# M3351 register map
File version: 1.0
Registers are 32-bit, read-write, reset 0x0 unless marked. A register's access mark holds for its fields unless they carry their own. Offsets are from the block's base; [hi:lo] are bit positions.

## LLSI0 — LLSI Register Map
Base 0x40088000
Same registers: LLSI2 0x40088200, LLSI4 0x40088400, LLSI6 0x40088600, LLSI8 0x40088800, LLSI1 0x40089000, LLSI3 0x40089200, LLSI5 0x40089400, LLSI7 0x40089600, LLSI9 0x40089800, LLSI0_NS 0x50088000, LLSI2_NS 0x50088200, LLSI4_NS 0x50088400, LLSI6_NS 0x50088600, LLSI8_NS 0x50088800, LLSI1_NS 0x50089000, LLSI3_NS 0x50089200, LLSI5_NS 0x50089400, LLSI7_NS 0x50089600, LLSI9_NS 0x50089800
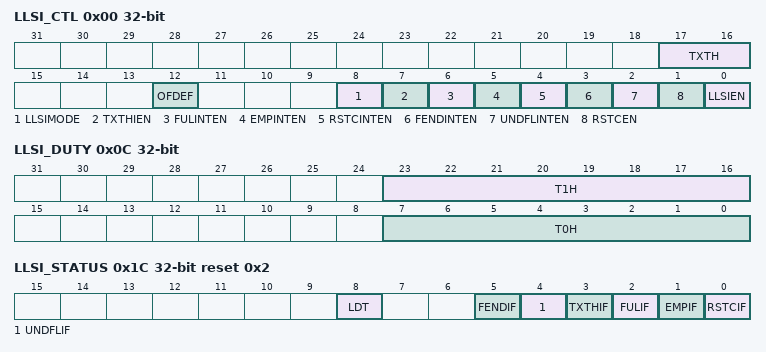
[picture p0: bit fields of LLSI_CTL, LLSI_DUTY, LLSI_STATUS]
0x00 LLSI_CTL — LLSI Control Register
  [17:16] TXTH — Transmit FIFO Threshold. If the valid data count of the transmit FIFO buffer is less than or equal to the TXTH setting, the TXTHIF bit will be set to 1, else the TXTHIF bit will be cleared to 0.
  [12] OFDEF — Output Format Define
    0=Output RGB format; 1=Output GRB format
  [8] LLSIMODE — LLSI Mode Select
    0=Software mode; 1=PDMA mode
  [7] TXTHIEN — Transmit FIFO Threshold Interrupt Enable Bit. Note: This bit is only supported in software mode.
    0=TX FIFO threshold interrupt Disabled; 1=TX FIFO threshold interrupt Enabled
  [6] FULINTEN — FIFO Full Interrupt Enable Bit. Note: If this bit is enabled, when the FULIF interrupt flag is set to 1, the LLSI interrupt signal is generated and inform to CPU.
    0=FIFO full interrupt Disabled; 1=FIFO full interrupt Enabled
  [5] EMPINTEN — FIFO Empty Interrupt Enable Bit. Note: If this bit is enabled, when the EMPIF interrupt flag is set to 1, the LLSI interrupt signal is generated and inform to CPU.
    0=FIFO empty interrupt Disabled; 1=FIFO empty interrupt Enabled
  [4] RSTCINTEN — Reset Command Interrupt Enable Bit. Note: If this bit is enabled, when the RSTCIF interrupt flag is set to 1, the LLSI interrupt signal is generated and inform to CPU.
    0=Reset command interrupt Disabled; 1=Reset command interrupt Enabled
  [3] FENDINTEN — Frame End Interrupt Enable Bit. Note: If this bit is enabled, when the FENDIF interrupt flag is set to 1, the LLSI interrupt signal is generated and inform to CPU.
    0=Frame end interrupt Disabled; 1=Frame end interrupt Enabled
  [2] UNDFLINTEN — Underflow Interrupt Enable Bit. Note: If this bit is enabled, when the UNDFLIF interrupt flag is set to 1, the LLSI interrupt signal is generated and inform to CPU.
    0=Underflow interrupt Disabled; 1=Underflow interrupt Enabled
  [1] RSTCEN — Reset Command Function Enable Bit. Note: If this bit is enabled, when FIFO and shift register are both empty, LLSI will send reset command out.
    0=Reset command function Disabled; 1=Reset command function Enabled
  [0] LLSIEN — LLSI Enable Bit
    0=LLSI Disabled; 1=LLSI Enabled
0x04 LLSI_RSTPERIOD — LLSI Reset Period Control Register
  [15:0] RSTPERIOD — Reset Command Period. This field is used to adjust the time of reset command.
0x08 LLSI_PERIOD — LLSI Period Control Register
  [7:0] PERIOD — LLSI Period Register. This field is used to define data transfer time (TH+TL).
0x0C LLSI_DUTY — LLSI Duty Control Register
  [23:16] T1H — T1H Data Register. This field is used to define the time of T1H.
  [7:0] T0H — T0H Data Register. This field is used to define the time of T0H.
0x10 LLSI_DATA wo
  [31:0] DATA — Data Transmit Register. The data transmit registers pass through the transmitted data into the 4-level transmit FIFO buffers.
0x14 LLSI_PCNT — LLSI Pixel Count Register
  [11:0] PCNT — Pixel Count Register. User should write a frame size to this register before transfer. For example, if there are a total of 5 LED (5 pixels) in frame, user should write 5 to this control register.
0x18 LLSI_CLKDIV — LLSI Clock Divider Register
  [7:0] DIVIDER — LLSI Clock Divider. It indicates the LLSI clock,
0x1C LLSI_STATUS reset 0x2
  [8] LDT — Last Data Transmit
  [5] FENDIF — Frame End Interrupt Flag. This bit indicates that LLSI has finished data transmission (FIFO empty shift register empty). When LLSI transfer finish (FIFO empty shift register empty) this bit is set to 1. User can use this flag to prepare data in advance. Software can write 1 to clear this bit.
  [4] UNDFLIF — Under Flow Interrupt Flag. Each transmission LLSI reads 3 bytes data from the FIFO. This bit is set to 1 when LLSI reads the FIFO and the valid data in FIFO is less than 3 bytes. Software can write 1 to clear this bit.
  [3] TXTHIF — Transmit FIFO Threshold Interrupt Flag
    0=The valid data count within the transmit FIFO buffer is larger than the setting value of TXTH; 1=The valid data count within the transmit FIFO buffer is less than or equal to the setting value of TXTH
  [2] FULIF — FIFO Full Interrupt Flag
    0=Transmit FIFO buffer is not full; 1=Transmit FIFO buffer is full
  [1] EMPIF — FIFO Empty Interrupt Flag
    0=Transmit FIFO buffer is not empty; 1=Transmit FIFO buffer is empty
  [0] RSTCIF — Reset Command Interrupt Flag. This bit indicates that LLSI has finished reset command transmission.
0x20 LLSI_OCTL — LLSI Output Control Register
  [0] IDOS — Idle Output Control
    0=Idle will output 0; 1=Idle will output 1
